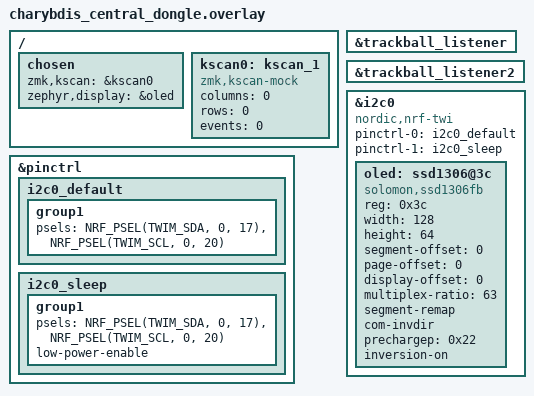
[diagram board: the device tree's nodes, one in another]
/*
 * Copyright (c) 2020 The ZMK Contributors
 *
 * SPDX-License-Identifier: MIT
 */

#include "charybdis.dtsi"
#include "split_input_common.dtsi"


/ {
    chosen {
        zmk,kscan = &kscan0;
        zephyr,display = &oled;
    };

    kscan0: kscan_1 {
        compatible = "zmk,kscan-mock";
        columns = <0>;
        rows = <0>;
        events = <0>;
    };
};

&trackball_listener {
    status = "okay";
};
&trackball_listener2 {
    status = "okay";
};

&pinctrl {
    i2c0_default: i2c0_default {
        group1 {
            psels = <NRF_PSEL(TWIM_SDA, 0, 17)>,
                <NRF_PSEL(TWIM_SCL, 0, 20)>;
        };
    };

    i2c0_sleep: i2c0_sleep {
        group1 {
            psels = <NRF_PSEL(TWIM_SDA, 0, 17)>,
                <NRF_PSEL(TWIM_SCL, 0, 20)>;
            low-power-enable;
        };
    };

}; 

&i2c0 {
	status = "okay";
	compatible = "nordic,nrf-twi";
    pinctrl-0 = <&i2c0_default>;
    pinctrl-1 = <&i2c0_sleep>;
	 oled: ssd1306@3c {
        compatible = "solomon,ssd1306fb";    // 改为 SSD1306 的兼容字符串
        reg = <0x3c>;                         // I2C 地址（通常与 SH1106 相同）
        width = <128>;                         // 屏幕宽度
        height = <64>;                          // 屏幕高度
        segment-offset = <0>;                   // 列偏移，SSD1306 通常为 0
        page-offset = <0>;                       // 页偏移
        display-offset = <0>;                    // 显示偏移
        multiplex-ratio = <63>;                  // 复用率（64 行，所以 63）
        segment-remap;                            // 列重映射（可选）
        com-invdir;                                // COM 方向反转（可选）
        prechargep = <0x22>;                       // 预充电周期（可选）
        inversion-on;                           // 移除或根据需要启用（SSD1306 可能也支持）
	};
};
